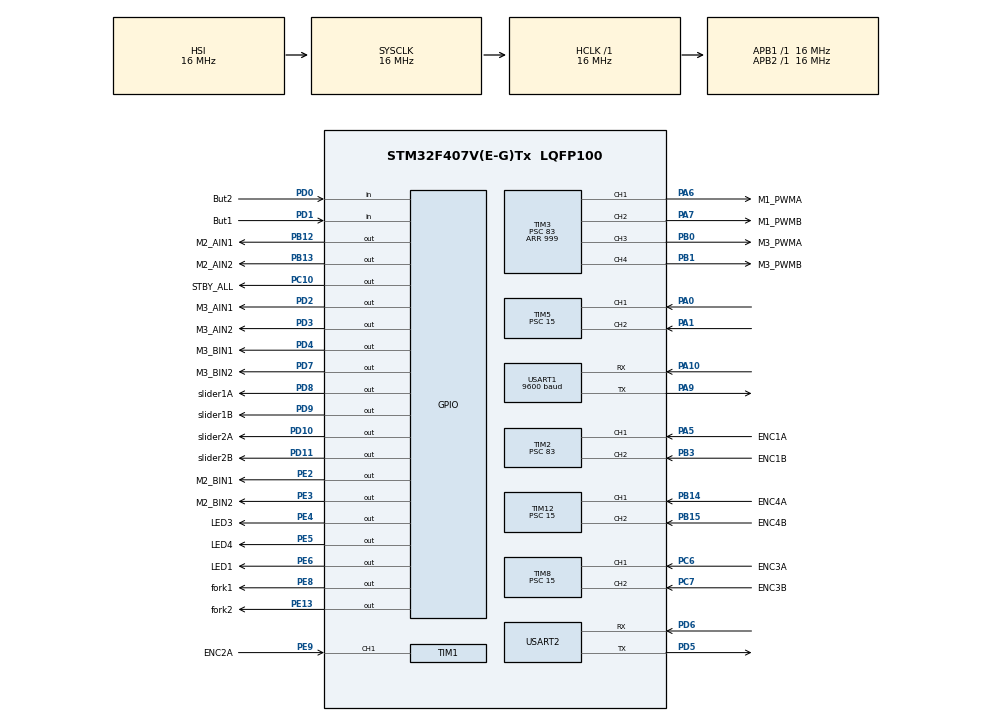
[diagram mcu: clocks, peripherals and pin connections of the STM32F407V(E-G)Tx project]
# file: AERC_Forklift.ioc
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Mcu.Family=STM32F4
Mcu.Name=STM32F407V(E-G)Tx
Mcu.Package=LQFP100
NVIC.PriorityGroup=NVIC_PRIORITYGROUP_4
NVIC.TIM1_CC_IRQn=true\:0\:0\:false\:false\:true\:true\:true\:true
NVIC.TIM2_IRQn=true\:0\:0\:false\:false\:true\:true\:true\:true
NVIC.TIM3_IRQn=true\:0\:0\:false\:false\:true\:true\:true\:true
NVIC.TIM5_IRQn=true\:0\:0\:false\:false\:true\:true\:true\:true
NVIC.TIM8_BRK_TIM12_IRQn=true\:0\:0\:false\:false\:true\:true\:true\:true
NVIC.TIM8_CC_IRQn=true\:0\:0\:false\:false\:true\:true\:true\:true
NVIC.USART1_IRQn=true\:5\:0\:true\:false\:true\:true\:true\:true
NVIC.USART2_IRQn=true\:0\:0\:false\:false\:true\:true\:true\:true
PA0-WKUP.GPIO_PuPd=GPIO_PULLUP
PA0-WKUP.Signal=S_TIM5_CH1
PA1.GPIO_PuPd=GPIO_PULLUP
PA1.Signal=S_TIM5_CH2
PA10.Mode=Asynchronous
PA10.Signal=USART1_RX
PA13.Mode=Serial_Wire
PA13.Signal=SYS_JTMS-SWDIO
PA14.Mode=Serial_Wire
PA14.Signal=SYS_JTCK-SWCLK
PA5.GPIO_Label=ENC1A
PA5.GPIO_PuPd=GPIO_PULLUP
PA5.Signal=S_TIM2_CH1_ETR
PA6.GPIO_Label=M1_PWMA
PA6.Signal=S_TIM3_CH1
PA7.GPIO_Label=M1_PWMB
PA7.Signal=S_TIM3_CH2
PA9.Mode=Asynchronous
PA9.Signal=USART1_TX
PB0.GPIO_Label=M3_PWMA
PB0.Signal=S_TIM3_CH3
PB1.GPIO_Label=M3_PWMB
PB1.Signal=S_TIM3_CH4
PB12.GPIO_Label=M2_AIN1
PB12.Signal=GPIO_Output
PB13.GPIO_Label=M2_AIN2
PB13.Signal=GPIO_Output
PB14.GPIO_Label=ENC4A
PB14.GPIO_PuPd=GPIO_PULLUP
PB14.Signal=S_TIM12_CH1
PB15.GPIO_Label=ENC4B
PB15.GPIO_PuPd=GPIO_PULLUP
PB15.Signal=S_TIM12_CH2
PB3.GPIO_Label=ENC1B
PB3.GPIO_PuPd=GPIO_PULLUP
PB3.Signal=S_TIM2_CH2
PC10.GPIO_Label=STBY_ALL
PC10.PinState=GPIO_PIN_SET
PC10.Signal=GPIO_Output
PC6.GPIO_Label=ENC3A
PC6.GPIO_PuPd=GPIO_PULLUP
PC6.Signal=S_TIM8_CH1
PC7.GPIO_Label=ENC3B
PC7.GPIO_PuPd=GPIO_PULLUP
PC7.Signal=S_TIM8_CH2
PD0.GPIO_Label=But2
PD0.Signal=GPIO_Input
PD1.GPIO_Label=But1
PD1.Signal=GPIO_Input
PD10.GPIO_Label=slider2A
PD10.Signal=GPIO_Output
PD11.GPIO_Label=slider2B
PD11.Signal=GPIO_Output
PD2.GPIO_Label=M3_AIN1
PD2.Signal=GPIO_Output
PD3.GPIO_Label=M3_AIN2
PD3.Signal=GPIO_Output
PD4.GPIO_Label=M3_BIN1
PD4.Signal=GPIO_Output
PD5.Mode=Asynchronous
PD5.Signal=USART2_TX
PD6.Mode=Asynchronous
PD6.Signal=USART2_RX
PD7.GPIO_Label=M3_BIN2
PD7.Signal=GPIO_Output
PD8.GPIO_Label=slider1A
PD8.Signal=GPIO_Output
PD9.GPIO_Label=slider1B
PD9.Signal=GPIO_Output
PE13.GPIO_Label=fork2
PE13.Signal=GPIO_Output
PE2.GPIO_Label=M2_BIN1
PE2.Signal=GPIO_Output
PE3.GPIO_Label=M2_BIN2
PE3.Signal=GPIO_Output
PE4.GPIO_Label=LED3
PE4.Signal=GPIO_Output
PE5.GPIO_Label=LED4
PE5.Signal=GPIO_Output
PE6.GPIO_Label=LED1
PE6.Signal=GPIO_Output
PE8.GPIO_Label=fork1 
PE8.Signal=GPIO_Output
PE9.GPIO_Label=ENC2A
PE9.GPIO_PuPd=GPIO_PULLUP
PE9.Signal=S_TIM1_CH1
PH0-OSC_IN.Mode=HSE-External-Oscillator
PH0-OSC_IN.Signal=RCC_OSC_IN
PH1-OSC_OUT.Mode=HSE-External-Oscillator
PH1-OSC_OUT.Signal=RCC_OSC_OUT
ProjectManager.HeapSize=0x200
ProjectManager.StackSize=0x400
ProjectManager.TargetToolchain=CMake
RCC.48MHZClocksFreq_Value=48000000
RCC.AHBFreq_Value=16000000
RCC.APB1Freq_Value=16000000
RCC.APB1TimFreq_Value=16000000
RCC.APB2Freq_Value=16000000
RCC.APB2TimFreq_Value=16000000
RCC.CortexFreq_Value=16000000
RCC.HCLKFreq_Value=16000000
RCC.HSE_VALUE=25000000
RCC.HSI_VALUE=16000000
RCC.LSE_VALUE=32768
RCC.SYSCLKFreq_VALUE=16000000
RCC.VCOOutputFreq_Value=192000000
SH.S_TIM12_CH1.0=TIM12_CH1,Input_Capture1_from_TI1
SH.S_TIM12_CH2.0=TIM12_CH2,Input_Capture2_from_TI2
SH.S_TIM1_CH1.0=TIM1_CH1,Input_Capture1_from_TI1
SH.S_TIM2_CH1_ETR.0=TIM2_CH1,Input_Capture1_from_TI1
SH.S_TIM2_CH2.0=TIM2_CH2,Input_Capture2_from_TI2
SH.S_TIM3_CH1.0=TIM3_CH1,PWM Generation1 CH1
SH.S_TIM3_CH2.0=TIM3_CH2,PWM Generation2 CH2
SH.S_TIM3_CH3.0=TIM3_CH3,PWM Generation3 CH3
SH.S_TIM3_CH4.0=TIM3_CH4,PWM Generation4 CH4
SH.S_TIM5_CH1.0=TIM5_CH1,Input_Capture1_from_TI1
SH.S_TIM5_CH2.0=TIM5_CH2,Input_Capture2_from_TI2
SH.S_TIM8_CH1.0=TIM8_CH1,Input_Capture1_from_TI1
SH.S_TIM8_CH2.0=TIM8_CH2,Input_Capture2_from_TI2
TIM1.Channel-Input_Capture1_from_TI1=TIM_CHANNEL_1
TIM1.Prescaler=167
TIM12.Channel-Input_Capture1_from_TI1=TIM_CHANNEL_1
TIM12.Channel-Input_Capture2_from_TI2=TIM_CHANNEL_2
TIM12.Prescaler=15
TIM2.Channel-Input_Capture1_from_TI1=TIM_CHANNEL_1
TIM2.Channel-Input_Capture2_from_TI2=TIM_CHANNEL_2
TIM2.Period=65535
TIM2.Prescaler=83
TIM3.Channel-PWM\ Generation1\ CH1=TIM_CHANNEL_1
TIM3.Channel-PWM\ Generation2\ CH2=TIM_CHANNEL_2
TIM3.Channel-PWM\ Generation3\ CH3=TIM_CHANNEL_3
TIM3.Channel-PWM\ Generation4\ CH4=TIM_CHANNEL_4
TIM3.Period=999
TIM3.Prescaler=83
TIM5.Channel-Input_Capture1_from_TI1=TIM_CHANNEL_1
TIM5.Channel-Input_Capture2_from_TI2=TIM_CHANNEL_2
TIM5.Period=65535
TIM5.Prescaler=15
TIM8.Channel-Input_Capture1_from_TI1=TIM_CHANNEL_1
TIM8.Channel-Input_Capture2_from_TI2=TIM_CHANNEL_2
TIM8.ICPolarity_CH1=TIM_INPUTCHANNELPOLARITY_RISING
TIM8.Prescaler=15
USART1.BaudRate=9600
USART1.VirtualMode=VM_ASYNC
USART2.VirtualMode=VM_ASYNC
VP_TIM1_VS_ClockSourceINT.Mode=Internal
VP_TIM2_VS_ClockSourceINT.Mode=Internal
board=custom

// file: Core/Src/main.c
/* USER CODE BEGIN Header */
/**
  ******************************************************************************
  * @file           : main.c
  * @brief          : Main program body
  ******************************************************************************
  * @attention
  *
  * Copyright (c) 2026 STMicroelectronics.
  * All rights reserved.
  *
  * This software is licensed under terms that can be found in the LICENSE file
  * in the root directory of this software component.
  * If no LICENSE file comes with this software, it is provided AS-IS.
  *
  ******************************************************************************
  */
/* USER CODE END Header */
#include "main.h"

/* USER CODE BEGIN Includes */
#include "mecanum.h"
#include "ps4.h"
#include "controller.h"
#include "stm32f4xx_hal.h"
#include "stm32f4xx_hal_gpio.h"
#include "fork.h"
/* USER CODE END Includes */

TIM_HandleTypeDef htim1;
TIM_HandleTypeDef htim2;
TIM_HandleTypeDef htim3;
TIM_HandleTypeDef htim5;
TIM_HandleTypeDef htim8;
TIM_HandleTypeDef htim12;

UART_HandleTypeDef huart1;
UART_HandleTypeDef huart2;

/* USER CODE BEGIN PV */
extern volatile int32_t enc_ticks[4];
extern volatile int test;
/* USER CODE END PV */

void SystemClock_Config(void);
static void MX_GPIO_Init(void);
static void MX_TIM3_Init(void);
static void MX_USART1_UART_Init(void);
static void MX_USART2_UART_Init(void);
static void MX_TIM1_Init(void);
static void MX_TIM2_Init(void);
static void MX_TIM8_Init(void);
static void MX_TIM12_Init(void);
static void MX_TIM5_Init(void);

int main(void)
{

  /* MCU Configuration--------------------------------------------------------*/

  /* Reset of all peripherals, Initializes the Flash interface and the Systick. */
  HAL_Init();

  /* Configure the system clock */
  SystemClock_Config();

  /* Initialize all configured peripherals */
  MX_GPIO_Init();
  MX_TIM3_Init();
  MX_USART1_UART_Init();
  MX_USART2_UART_Init();
  MX_TIM1_Init();
  MX_TIM2_Init();
  MX_TIM8_Init();
  MX_TIM12_Init();
  MX_TIM5_Init();
  /* USER CODE BEGIN 2 */
  Mecanum_Init();
  Fork_Init();
  Controller_Init();
  /* USER CODE END 2 */

  /* Infinite loop */
  /* USER CODE BEGIN WHILE */
  while (1)
  {
    Controller_Update();
    HAL_Delay(10);
    /* USER CODE END WHILE */

  }
}

void SystemClock_Config(void)
{
  RCC_OscInitTypeDef RCC_OscInitStruct = {0};
  RCC_ClkInitTypeDef RCC_ClkInitStruct = {0};

  /** Configure the main internal regulator output voltage
  */
  __HAL_RCC_PWR_CLK_ENABLE();
  __HAL_PWR_VOLTAGESCALING_CONFIG(PWR_REGULATOR_VOLTAGE_SCALE1);

  /** Initializes the RCC Oscillators according to the specified parameters
  * in the RCC_OscInitTypeDef structure.
  */
  RCC_OscInitStruct.OscillatorType = RCC_OSCILLATORTYPE_HSI;
  RCC_OscInitStruct.HSIState = RCC_HSI_ON;
  RCC_OscInitStruct.HSICalibrationValue = RCC_HSICALIBRATION_DEFAULT;
  RCC_OscInitStruct.PLL.PLLState = RCC_PLL_NONE;
  if (HAL_RCC_OscConfig(&RCC_OscInitStruct) != HAL_OK)
  {
    Error_Handler();
  }

  /** Initializes the CPU, AHB and APB buses clocks
  */
  RCC_ClkInitStruct.ClockType = RCC_CLOCKTYPE_HCLK|RCC_CLOCKTYPE_SYSCLK
                              |RCC_CLOCKTYPE_PCLK1|RCC_CLOCKTYPE_PCLK2;
  RCC_ClkInitStruct.SYSCLKSource = RCC_SYSCLKSOURCE_HSI;
  RCC_ClkInitStruct.AHBCLKDivider = RCC_SYSCLK_DIV1;
  RCC_ClkInitStruct.APB1CLKDivider = RCC_HCLK_DIV1;
  RCC_ClkInitStruct.APB2CLKDivider = RCC_HCLK_DIV1;

  if (HAL_RCC_ClockConfig(&RCC_ClkInitStruct, FLASH_LATENCY_0) != HAL_OK)
  {
    Error_Handler();
  }
}

static void MX_TIM1_Init(void)
{

  TIM_ClockConfigTypeDef sClockSourceConfig = {0};
  TIM_MasterConfigTypeDef sMasterConfig = {0};
  TIM_IC_InitTypeDef sConfigIC = {0};

  htim1.Instance = TIM1;
  htim1.Init.Prescaler = 167;
  htim1.Init.CounterMode = TIM_COUNTERMODE_UP;
  htim1.Init.Period = 65535;
  htim1.Init.ClockDivision = TIM_CLOCKDIVISION_DIV1;
  htim1.Init.RepetitionCounter = 0;
  htim1.Init.AutoReloadPreload = TIM_AUTORELOAD_PRELOAD_DISABLE;
  if (HAL_TIM_Base_Init(&htim1) != HAL_OK)
  {
    Error_Handler();
  }
  sClockSourceConfig.ClockSource = TIM_CLOCKSOURCE_INTERNAL;
  if (HAL_TIM_ConfigClockSource(&htim1, &sClockSourceConfig) != HAL_OK)
  {
    Error_Handler();
  }
  if (HAL_TIM_IC_Init(&htim1) != HAL_OK)
  {
    Error_Handler();
  }
  sMasterConfig.MasterOutputTrigger = TIM_TRGO_RESET;
  sMasterConfig.MasterSlaveMode = TIM_MASTERSLAVEMODE_DISABLE;
  if (HAL_TIMEx_MasterConfigSynchronization(&htim1, &sMasterConfig) != HAL_OK)
  {
    Error_Handler();
  }
  sConfigIC.ICPolarity = TIM_INPUTCHANNELPOLARITY_RISING;
  sConfigIC.ICSelection = TIM_ICSELECTION_DIRECTTI;
  sConfigIC.ICPrescaler = TIM_ICPSC_DIV1;
  sConfigIC.ICFilter = 0;
  if (HAL_TIM_IC_ConfigChannel(&htim1, &sConfigIC, TIM_CHANNEL_1) != HAL_OK)
  {
    Error_Handler();
  }

}

static void MX_TIM2_Init(void)
{

  TIM_ClockConfigTypeDef sClockSourceConfig = {0};
  TIM_MasterConfigTypeDef sMasterConfig = {0};
  TIM_IC_InitTypeDef sConfigIC = {0};

  htim2.Instance = TIM2;
  htim2.Init.Prescaler = 83;
  htim2.Init.CounterMode = TIM_COUNTERMODE_UP;
  htim2.Init.Period = 65535;
  htim2.Init.ClockDivision = TIM_CLOCKDIVISION_DIV1;
  htim2.Init.AutoReloadPreload = TIM_AUTORELOAD_PRELOAD_DISABLE;
  if (HAL_TIM_Base_Init(&htim2) != HAL_OK)
  {
    Error_Handler();
  }
  sClockSourceConfig.ClockSource = TIM_CLOCKSOURCE_INTERNAL;
  if (HAL_TIM_ConfigClockSource(&htim2, &sClockSourceConfig) != HAL_OK)
  {
    Error_Handler();
  }
  if (HAL_TIM_IC_Init(&htim2) != HAL_OK)
  {
    Error_Handler();
  }
  sMasterConfig.MasterOutputTrigger = TIM_TRGO_RESET;
  sMasterConfig.MasterSlaveMode = TIM_MASTERSLAVEMODE_DISABLE;
  if (HAL_TIMEx_MasterConfigSynchronization(&htim2, &sMasterConfig) != HAL_OK)
  {
    Error_Handler();
  }
  sConfigIC.ICPolarity = TIM_INPUTCHANNELPOLARITY_RISING;
  sConfigIC.ICSelection = TIM_ICSELECTION_DIRECTTI;
  sConfigIC.ICPrescaler = TIM_ICPSC_DIV1;
  sConfigIC.ICFilter = 0;
  if (HAL_TIM_IC_ConfigChannel(&htim2, &sConfigIC, TIM_CHANNEL_1) != HAL_OK)
  {
    Error_Handler();
  }
  if (HAL_TIM_IC_ConfigChannel(&htim2, &sConfigIC, TIM_CHANNEL_2) != HAL_OK)
  {
    Error_Handler();
  }

}

static void MX_TIM3_Init(void)
{

  TIM_MasterConfigTypeDef sMasterConfig = {0};
  TIM_OC_InitTypeDef sConfigOC = {0};

  htim3.Instance = TIM3;
  htim3.Init.Prescaler = 83;
  htim3.Init.CounterMode = TIM_COUNTERMODE_UP;
  htim3.Init.Period = 999;
  htim3.Init.ClockDivision = TIM_CLOCKDIVISION_DIV1;
  htim3.Init.AutoReloadPreload = TIM_AUTORELOAD_PRELOAD_DISABLE;
  if (HAL_TIM_PWM_Init(&htim3) != HAL_OK)
  {
    Error_Handler();
  }
  sMasterConfig.MasterOutputTrigger = TIM_TRGO_RESET;
  sMasterConfig.MasterSlaveMode = TIM_MASTERSLAVEMODE_DISABLE;
  if (HAL_TIMEx_MasterConfigSynchronization(&htim3, &sMasterConfig) != HAL_OK)
  {
    Error_Handler();
  }
  sConfigOC.OCMode = TIM_OCMODE_PWM1;
  sConfigOC.Pulse = 0;
  sConfigOC.OCPolarity = TIM_OCPOLARITY_HIGH;
  sConfigOC.OCFastMode = TIM_OCFAST_DISABLE;
  if (HAL_TIM_PWM_ConfigChannel(&htim3, &sConfigOC, TIM_CHANNEL_1) != HAL_OK)
  {
    Error_Handler();
  }
  if (HAL_TIM_PWM_ConfigChannel(&htim3, &sConfigOC, TIM_CHANNEL_2) != HAL_OK)
  {
    Error_Handler();
  }
  if (HAL_TIM_PWM_ConfigChannel(&htim3, &sConfigOC, TIM_CHANNEL_3) != HAL_OK)
  {
    Error_Handler();
  }
  if (HAL_TIM_PWM_ConfigChannel(&htim3, &sConfigOC, TIM_CHANNEL_4) != HAL_OK)
  {
    Error_Handler();
  }
  HAL_TIM_MspPostInit(&htim3);

}

static void MX_TIM5_Init(void)
{

  TIM_MasterConfigTypeDef sMasterConfig = {0};
  TIM_IC_InitTypeDef sConfigIC = {0};

  htim5.Instance = TIM5;
  htim5.Init.Prescaler = 15;
  htim5.Init.CounterMode = TIM_COUNTERMODE_UP;
  htim5.Init.Period = 65535;
  htim5.Init.ClockDivision = TIM_CLOCKDIVISION_DIV1;
  htim5.Init.AutoReloadPreload = TIM_AUTORELOAD_PRELOAD_DISABLE;
  if (HAL_TIM_IC_Init(&htim5) != HAL_OK)
  {
    Error_Handler();
  }
  sMasterConfig.MasterOutputTrigger = TIM_TRGO_RESET;
  sMasterConfig.MasterSlaveMode = TIM_MASTERSLAVEMODE_DISABLE;
  if (HAL_TIMEx_MasterConfigSynchronization(&htim5, &sMasterConfig) != HAL_OK)
  {
    Error_Handler();
  }
  sConfigIC.ICPolarity = TIM_INPUTCHANNELPOLARITY_RISING;
  sConfigIC.ICSelection = TIM_ICSELECTION_DIRECTTI;
  sConfigIC.ICPrescaler = TIM_ICPSC_DIV1;
  sConfigIC.ICFilter = 0;
  if (HAL_TIM_IC_ConfigChannel(&htim5, &sConfigIC, TIM_CHANNEL_1) != HAL_OK)
  {
    Error_Handler();
  }
  if (HAL_TIM_IC_ConfigChannel(&htim5, &sConfigIC, TIM_CHANNEL_2) != HAL_OK)
  {
    Error_Handler();
  }

}

static void MX_TIM8_Init(void)
{

  TIM_MasterConfigTypeDef sMasterConfig = {0};
  TIM_IC_InitTypeDef sConfigIC = {0};

  htim8.Instance = TIM8;
  htim8.Init.Prescaler = 15;
  htim8.Init.CounterMode = TIM_COUNTERMODE_UP;
  htim8.Init.Period = 65535;
  htim8.Init.ClockDivision = TIM_CLOCKDIVISION_DIV1;
  htim8.Init.RepetitionCounter = 0;
  htim8.Init.AutoReloadPreload = TIM_AUTORELOAD_PRELOAD_DISABLE;
  if (HAL_TIM_IC_Init(&htim8) != HAL_OK)
  {
    Error_Handler();
  }
  sMasterConfig.MasterOutputTrigger = TIM_TRGO_RESET;
  sMasterConfig.MasterSlaveMode = TIM_MASTERSLAVEMODE_DISABLE;
  if (HAL_TIMEx_MasterConfigSynchronization(&htim8, &sMasterConfig) != HAL_OK)
  {
    Error_Handler();
  }
  sConfigIC.ICPolarity = TIM_INPUTCHANNELPOLARITY_RISING;
  sConfigIC.ICSelection = TIM_ICSELECTION_DIRECTTI;
  sConfigIC.ICPrescaler = TIM_ICPSC_DIV1;
  sConfigIC.ICFilter = 0;
  if (HAL_TIM_IC_ConfigChannel(&htim8, &sConfigIC, TIM_CHANNEL_1) != HAL_OK)
  {
    Error_Handler();
  }
  if (HAL_TIM_IC_ConfigChannel(&htim8, &sConfigIC, TIM_CHANNEL_2) != HAL_OK)
  {
    Error_Handler();
  }

}

static void MX_TIM12_Init(void)
{

  TIM_IC_InitTypeDef sConfigIC = {0};

  htim12.Instance = TIM12;
  htim12.Init.Prescaler = 15;
  htim12.Init.CounterMode = TIM_COUNTERMODE_UP;
  htim12.Init.Period = 65535;
  htim12.Init.ClockDivision = TIM_CLOCKDIVISION_DIV1;
  htim12.Init.AutoReloadPreload = TIM_AUTORELOAD_PRELOAD_DISABLE;
  if (HAL_TIM_IC_Init(&htim12) != HAL_OK)
  {
    Error_Handler();
  }
  sConfigIC.ICPolarity = TIM_INPUTCHANNELPOLARITY_RISING;
  sConfigIC.ICSelection = TIM_ICSELECTION_DIRECTTI;
  sConfigIC.ICPrescaler = TIM_ICPSC_DIV1;
  sConfigIC.ICFilter = 0;
  if (HAL_TIM_IC_ConfigChannel(&htim12, &sConfigIC, TIM_CHANNEL_1) != HAL_OK)
  {
    Error_Handler();
  }
  if (HAL_TIM_IC_ConfigChannel(&htim12, &sConfigIC, TIM_CHANNEL_2) != HAL_OK)
  {
    Error_Handler();
  }

}

static void MX_USART1_UART_Init(void)
{

  huart1.Instance = USART1;
  huart1.Init.BaudRate = 9600;
  huart1.Init.WordLength = UART_WORDLENGTH_8B;
  huart1.Init.StopBits = UART_STOPBITS_1;
  huart1.Init.Parity = UART_PARITY_NONE;
  huart1.Init.Mode = UART_MODE_TX_RX;
  huart1.Init.HwFlowCtl = UART_HWCONTROL_NONE;
  huart1.Init.OverSampling = UART_OVERSAMPLING_16;
  if (HAL_UART_Init(&huart1) != HAL_OK)
  {
    Error_Handler();
  }

}

static void MX_USART2_UART_Init(void)
{

  huart2.Instance = USART2;
  huart2.Init.BaudRate = 115200;
  huart2.Init.WordLength = UART_WORDLENGTH_8B;
  huart2.Init.StopBits = UART_STOPBITS_1;
  huart2.Init.Parity = UART_PARITY_NONE;
  huart2.Init.Mode = UART_MODE_TX_RX;
  huart2.Init.HwFlowCtl = UART_HWCONTROL_NONE;
  huart2.Init.OverSampling = UART_OVERSAMPLING_16;
  if (HAL_UART_Init(&huart2) != HAL_OK)
  {
    Error_Handler();
  }

}

static void MX_GPIO_Init(void)
{
  GPIO_InitTypeDef GPIO_InitStruct = {0};

  /* GPIO Ports Clock Enable */
  __HAL_RCC_GPIOE_CLK_ENABLE();
  __HAL_RCC_GPIOH_CLK_ENABLE();
  __HAL_RCC_GPIOA_CLK_ENABLE();
  __HAL_RCC_GPIOB_CLK_ENABLE();
  __HAL_RCC_GPIOD_CLK_ENABLE();
  __HAL_RCC_GPIOC_CLK_ENABLE();

  /*Configure GPIO pin Output Level */
  HAL_GPIO_WritePin(GPIOE, M2_BIN1_Pin|M2_BIN2_Pin|LED3_Pin|LED4_Pin
                          |LED1_Pin|fork1_Pin|fork2_Pin, GPIO_PIN_RESET);

  /*Configure GPIO pin Output Level */
  HAL_GPIO_WritePin(GPIOB, M2_AIN1_Pin|M2_AIN2_Pin, GPIO_PIN_RESET);

  /*Configure GPIO pin Output Level */
  HAL_GPIO_WritePin(GPIOD, slider1A_Pin|slider1B_Pin|slider2A_Pin|slider2B_Pin
                          |M3_AIN1_Pin|M3_AIN2_Pin|M3_BIN1_Pin|M3_BIN2_Pin, GPIO_PIN_RESET);

  /*Configure GPIO pin Output Level */
  HAL_GPIO_WritePin(STBY_ALL_GPIO_Port, STBY_ALL_Pin, GPIO_PIN_SET);

  /*Configure GPIO pins : M2_BIN1_Pin M2_BIN2_Pin LED3_Pin LED4_Pin
                           LED1_Pin fork1_Pin fork2_Pin */
  GPIO_InitStruct.Pin = M2_BIN1_Pin|M2_BIN2_Pin|LED3_Pin|LED4_Pin
                          |LED1_Pin|fork1_Pin|fork2_Pin;
  GPIO_InitStruct.Mode = GPIO_MODE_OUTPUT_PP;
  GPIO_InitStruct.Pull = GPIO_NOPULL;
  GPIO_InitStruct.Speed = GPIO_SPEED_FREQ_LOW;
  HAL_GPIO_Init(GPIOE, &GPIO_InitStruct);

  /*Configure GPIO pins : M2_AIN1_Pin M2_AIN2_Pin */
  GPIO_InitStruct.Pin = M2_AIN1_Pin|M2_AIN2_Pin;
  GPIO_InitStruct.Mode = GPIO_MODE_OUTPUT_PP;
  GPIO_InitStruct.Pull = GPIO_NOPULL;
  GPIO_InitStruct.Speed = GPIO_SPEED_FREQ_LOW;
  HAL_GPIO_Init(GPIOB, &GPIO_InitStruct);

  /*Configure GPIO pins : slider1A_Pin slider1B_Pin slider2A_Pin slider2B_Pin
                           M3_AIN1_Pin M3_AIN2_Pin M3_BIN1_Pin M3_BIN2_Pin */
  GPIO_InitStruct.Pin = slider1A_Pin|slider1B_Pin|slider2A_Pin|slider2B_Pin
                          |M3_AIN1_Pin|M3_AIN2_Pin|M3_BIN1_Pin|M3_BIN2_Pin;
  GPIO_InitStruct.Mode = GPIO_MODE_OUTPUT_PP;
  GPIO_InitStruct.Pull = GPIO_NOPULL;
  GPIO_InitStruct.Speed = GPIO_SPEED_FREQ_LOW;
  HAL_GPIO_Init(GPIOD, &GPIO_InitStruct);

  /*Configure GPIO pin : STBY_ALL_Pin */
  GPIO_InitStruct.Pin = STBY_ALL_Pin;
  GPIO_InitStruct.Mode = GPIO_MODE_OUTPUT_PP;
  GPIO_InitStruct.Pull = GPIO_NOPULL;
  GPIO_InitStruct.Speed = GPIO_SPEED_FREQ_LOW;
  HAL_GPIO_Init(STBY_ALL_GPIO_Port, &GPIO_InitStruct);

  /*Configure GPIO pins : But2_Pin But1_Pin */
  GPIO_InitStruct.Pin = But2_Pin|But1_Pin;
  GPIO_InitStruct.Mode = GPIO_MODE_INPUT;
  GPIO_InitStruct.Pull = GPIO_NOPULL;
  HAL_GPIO_Init(GPIOD, &GPIO_InitStruct);

}

void Error_Handler(void)
{
  __disable_irq();
  while (1)
  {
  }
}
